# STM32F412xG register map
File version: 1.0
Registers are 32-bit, read-write, reset 0x0 unless marked. A register's access mark holds for its fields unless they carry their own. Offsets are from the block's base; [hi:lo] are bit positions; {n}, {i} and the like mark numbered series.

## NVIC — Nested Vectored Interrupt Controller
Base 0xE000E000
0x04 ICTR ro — Interrupt Controller Type Register
  [3:0] INTLINESNUM — Total number of interrupt lines in groups
{0x100+4i} ISER{i} (i=0..2) — Interrupt Set-Enable Register
  [31:0] SETENA
{0x180+4i} ICER{i} (i=0..2) — Interrupt Clear-Enable Register
  [31:0] CLRENA
{0x200+4i} ISPR{i} (i=0..2) — Interrupt Set-Pending Register
  [31:0] SETPEND
{0x280+4i} ICPR{i} (i=0..2) — Interrupt Clear-Pending Register
  [31:0] CLRPEND
{0x300+4i} IABR{i} ro (i=0..2) — Interrupt Active Bit Register
  [31:0] ACTIVE
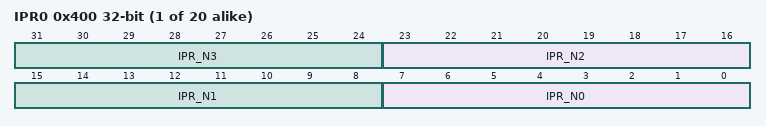
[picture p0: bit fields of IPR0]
{0x400+4i} IPR{i} (i=0..19) — Interrupt Priority Register
  [8n+7:8n] IPR_N{n} (n=0..3)
0xF00 STIR wo — Software Triggered Interrupt Register
  [8:0] INTID — interrupt to be triggered

## TIM6 — Basic timers
Base 0x40001000
Same registers: TIM7 0x40001400
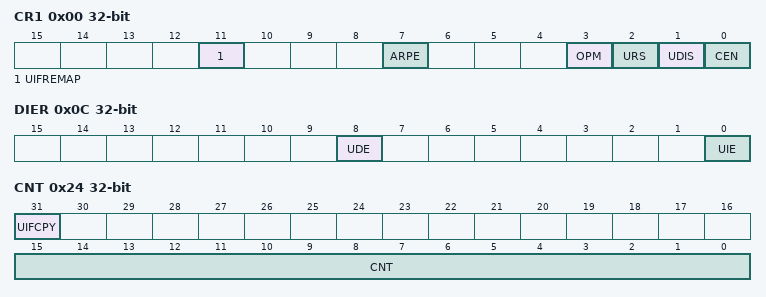
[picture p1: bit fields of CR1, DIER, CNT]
0x00 CR1 — control register 1
  [11] UIFREMAP — UIF status bit remapping
  [7] ARPE — Auto-reload preload enable
  [3] OPM — One-pulse mode
  [2] URS — Update request source
  [1] UDIS — Update disable
  [0] CEN — Counter enable
0x04 CR2 — control register 2
  [6:4] MMS — Master mode selection
0x0C DIER — DMA/Interrupt enable register
  [8] UDE — Update DMA request enable
  [0] UIE — Update interrupt enable
0x10 SR — status register
  [0] UIF — Update interrupt flag
0x14 EGR wo — event generation register
  [0] UG — Update generation
0x24 CNT access per field — counter
  [31] UIFCPY ro — UIF Copy
  [15:0] CNT rw — Low counter value
0x28 PSC — prescaler
  [15:0] PSC — Prescaler value
0x2C ARR — auto-reload register
  [15:0] ARR — Low Auto-reload value

## RNG — Random number generator
Base 0x50060800
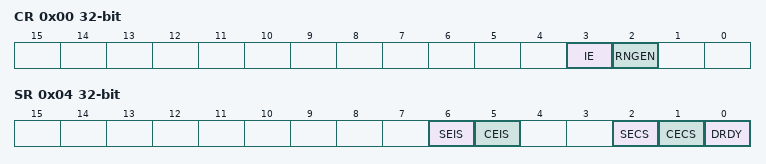
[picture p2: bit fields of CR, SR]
0x00 CR — control register
  [3] IE — Interrupt enable
  [2] RNGEN — Random number generator enable
0x04 SR access per field — status register
  [6] SEIS rw — Seed error interrupt status
  [5] CEIS rw — Clock error interrupt status
  [2] SECS ro — Seed error current status
  [1] CECS ro — Clock error current status
  [0] DRDY ro — Data ready
0x08 DR ro — data register
  [31:0] RNDATA — Random data

## I2C4 — Inter-integrated circuit
Base 0x40006000
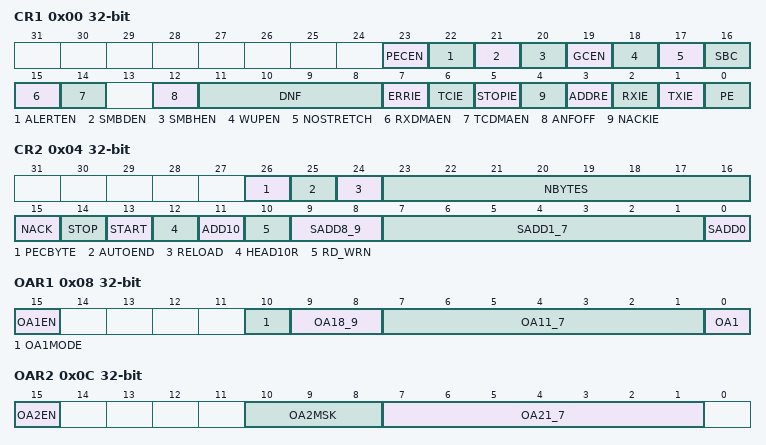
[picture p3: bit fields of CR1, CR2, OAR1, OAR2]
0x00 CR1 — Control register 1
  [23] PECEN
  [22] ALERTEN
  [21] SMBDEN
  [20] SMBHEN
  [19] GCEN
  [18] WUPEN
  [17] NOSTRETCH
  [16] SBC
  [15] RXDMAEN
  [14] TCDMAEN
  [12] ANFOFF
  [11:8] DNF
  [7] ERRIE
  [6] TCIE
  [5] STOPIE
  [4] NACKIE
  [3] ADDRE
  [2] RXIE
  [1] TXIE
  [0] PE — Peripheral enable
0x04 CR2 — Control register 2
  [26] PECBYTE — Packet error checking byte
  [25] AUTOEND — Automatic end mode
  [24] RELOAD — NBYTES reload mode
  [23:16] NBYTES — Number of bytes
  [15] NACK — NACK generation
  [14] STOP — Stop generation
  [13] START — Start generation
  [12] HEAD10R — 10-bit address header only read direction
  [11] ADD10 — 10-bit addressing mode
  [10] RD_WRN — Transfer direction
  [9:8] SADD8_9 — Slave address bit 8_9
  [7:1] SADD1_7 — Slave address bit 7_1
  [0] SADD0 — Slave address bit 0
0x08 OAR1 — Own address register 1
  [15] OA1EN, [10] OA1MODE, [9:8] OA18_9, [7:1] OA11_7, [0] OA1
0x0C OAR2 — Own address register 2
  [15] OA2EN, [10:8] OA2MSK, [7:1] OA21_7
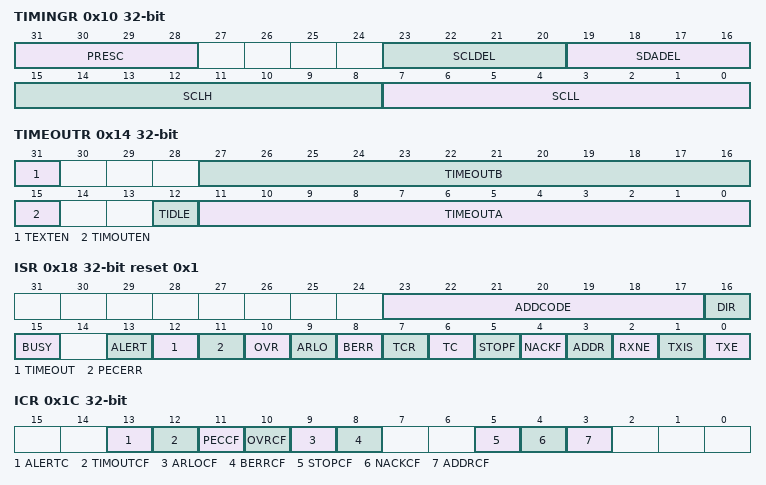
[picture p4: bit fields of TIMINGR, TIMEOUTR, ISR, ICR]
0x10 TIMINGR — Timing register
  [31:28] PRESC, [23:20] SCLDEL, [19:16] SDADEL, [15:8] SCLH, [7:0] SCLL
0x14 TIMEOUTR — Timeout register
  [31] TEXTEN, [27:16] TIMEOUTB, [15] TIMOUTEN, [12] TIDLE, [11:0] TIMEOUTA
0x18 ISR access per field reset 0x1 — Interrupt and Status register
  [23:17] ADDCODE ro, [16] DIR ro, [15] BUSY ro, [13] ALERT ro, [12] TIMEOUT ro, [11] PECERR ro, [10] OVR ro, [9] ARLO ro, [8] BERR ro, [7] TCR ro, [6] TC ro, [5] STOPF ro, [4] NACKF ro, [3] ADDR ro, [2] RXNE ro, [1] TXIS rw, [0] TXE rw
0x1C ICR wo — Interrupt clear register
  [13] ALERTC, [12] TIMOUTCF, [11] PECCF, [10] OVRCF, [9] ARLOCF, [8] BERRCF, [5] STOPCF, [4] NACKCF, [3] ADDRCF
0x20 PECR ro — PEC register
  [7:0] PEC
0x24 RXDR ro — Receive data register
  [7:0] RXDATA
0x28 TXDR — Transmit data register
  [7:0] TXDATA
